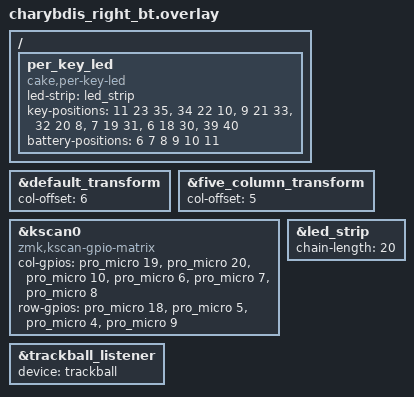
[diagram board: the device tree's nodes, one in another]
#include "../charybdis_common/charybdis.dtsi"
#include "../charybdis_common/charybdis_underglow.dtsi"
#include "../charybdis_trackball/charybdis_pmw3610.dtsi"
#include "../../config/trackball/charybdis_pointer.dtsi"

// The matrix transform is 6 columns over because the left half is 6 columns wide.
&default_transform {
	col-offset = <6>;
};

&five_column_transform {
	col-offset = <5>;
};

// KSCAN matrix
&kscan0 {
	compatible = "zmk,kscan-gpio-matrix";
	
	col-gpios
		= <&pro_micro 19 (GPIO_ACTIVE_HIGH | GPIO_PULL_DOWN)>
		, <&pro_micro 20 (GPIO_ACTIVE_HIGH | GPIO_PULL_DOWN)>
		, <&pro_micro 10 (GPIO_ACTIVE_HIGH | GPIO_PULL_DOWN)>
		, <&pro_micro 6 (GPIO_ACTIVE_HIGH | GPIO_PULL_DOWN)>
		, <&pro_micro 7 (GPIO_ACTIVE_HIGH | GPIO_PULL_DOWN)>
		, <&pro_micro 8 (GPIO_ACTIVE_HIGH | GPIO_PULL_DOWN)>
		;

	row-gpios
		= <&pro_micro 18 GPIO_ACTIVE_HIGH>
		, <&pro_micro 5 GPIO_ACTIVE_HIGH>
		, <&pro_micro 4 GPIO_ACTIVE_HIGH>
		, <&pro_micro 9 GPIO_ACTIVE_HIGH>
		;
};

/* enable the listener on central */
&trackball_listener {
    status = "okay";
    device = <&trackball>;
};

/* One LED per key: 18 main + 2 thumb */
&led_strip {
	chain-length = <20>;
};

/*
 * Per-key LEDs: light the pressed key in a random rainbow colour.
 * Chain order (viewed from the top): zig-zag down/up the columns starting at
 * the top of the outer pinky column, then the inner thumb, then the outer thumb.
 * Keymap positions on this half: row r spans 12r+6 (inner) .. 12r+11 (pinky);
 * thumbs are 39 (inner) and 40 (outer).
 */
/ {
	per_key_led {
		compatible = "cake,per-key-led";
		led-strip = <&led_strip>;
		key-positions
			= <11 23 35>	/* pinky col, down */
			, <34 22 10>	/* ring col, up */
			, < 9 21 33>	/* middle col, down */
			, <32 20  8>	/* index col, up */
			, < 7 19 31>	/* index inner col, down */
			, < 6 18 30>	/* innermost col (Y H N), down */
			, <39 40>	/* thumbs: inner, outer */
			;
		/* &kb_status: top row, filling from the inner column outwards */
		battery-positions = <6 7 8 9 10 11>;
	};
};
